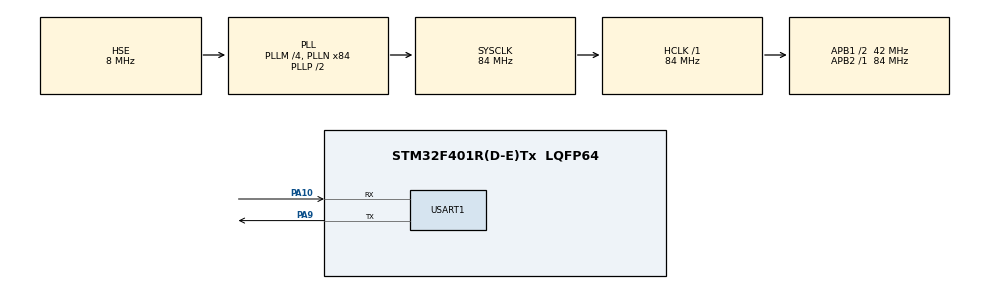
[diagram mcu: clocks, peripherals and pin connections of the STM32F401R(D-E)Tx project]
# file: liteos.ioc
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Mcu.Family=STM32F4
Mcu.Name=STM32F401R(D-E)Tx
Mcu.Package=LQFP64
NVIC.PriorityGroup=NVIC_PRIORITYGROUP_4
PA10.Mode=Asynchronous
PA10.Signal=USART1_RX
PA13.Mode=Serial_Wire
PA13.Signal=SYS_JTMS-SWDIO
PA14.Mode=Serial_Wire
PA14.Signal=SYS_JTCK-SWCLK
PA9.Mode=Asynchronous
PA9.Signal=USART1_TX
PH0\ -\ OSC_IN.Mode=HSE-External-Oscillator
PH0\ -\ OSC_IN.Signal=RCC_OSC_IN
PH1\ -\ OSC_OUT.Mode=HSE-External-Oscillator
PH1\ -\ OSC_OUT.Signal=RCC_OSC_OUT
ProjectManager.HeapSize=0x200
ProjectManager.StackSize=0x400
ProjectManager.TargetToolchain=STM32CubeIDE
RCC.48MHZClocksFreq_Value=42000000
RCC.AHBFreq_Value=84000000
RCC.APB1CLKDivider=RCC_HCLK_DIV2
RCC.APB1Freq_Value=42000000
RCC.APB1TimFreq_Value=84000000
RCC.APB2Freq_Value=84000000
RCC.APB2TimFreq_Value=84000000
RCC.CortexFreq_Value=84000000
RCC.HCLKFreq_Value=84000000
RCC.HSE_VALUE=8000000
RCC.HSI_VALUE=16000000
RCC.LSE_VALUE=32768
RCC.PLLM=4
RCC.PLLN=84
RCC.PLLSourceVirtual=RCC_PLLSOURCE_HSE
RCC.SYSCLKFreq_VALUE=84000000
RCC.SYSCLKSource=RCC_SYSCLKSOURCE_PLLCLK
RCC.VCOOutputFreq_Value=168000000
USART1.VirtualMode=VM_ASYNC
board=custom

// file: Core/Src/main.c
/* USER CODE BEGIN Header */
/**
  ******************************************************************************
  * @file           : main.c
  * @brief          : Main program body
  ******************************************************************************
  * @attention
  *
  * Copyright (c) 2023 STMicroelectronics.
  * All rights reserved.
  *
  * This software is licensed under terms that can be found in the LICENSE file
  * in the root directory of this software component.
  * If no LICENSE file comes with this software, it is provided AS-IS.
  *
  ******************************************************************************
  */
/* USER CODE END Header */
#include "main.h"
#include "usart.h"
#include "gpio.h"

/* USER CODE BEGIN Includes */
#include "stdio.h"
//#include "los_sys.h"
//#include "los_task.h"
#include "los_memory.h"
#include "string.h"
#include "los_task.h"

/* USER CODE END Includes */

/* USER CODE BEGIN PV */
UINT32 TASK1_Handle;
UINT32 TASK2_Handle;
/* USER CODE END PV */

void SystemClock_Config(void);

/* USER CODE BEGIN 0 */
#ifdef __GNUC__
#define PUTCHAR_PROTOTYPE int __io_putchar(int ch)
#else
#define PUTCHAR_PROTOTYPE int fputc(int ch, FILE *f)
#endif

PUTCHAR_PROTOTYPE
{
    HAL_UART_Transmit(&huart1, (uint8_t *)&ch, 1 , 0xffff);
    return ch;
}

static void Task1(VOID)
{
    unsigned int sp = 1;
    printf("task1 start\n");
    while(1) {

        printf("clock: %ud\n",sp);
        LOS_TaskDelay(100);
    }
}
static void Task2(VOID)
{
    unsigned int sp = 1;
    printf("task2 start\n");
    while(1) {
        printf("clock: %ud\n",sp);
        LOS_TaskDelay(50);
    }
}
UINT32  AppTaskCreate(UINT32 *Handle,UINT32 prio,char* task_name,TSK_ENTRY_FUNC task_func,UINT32 stack_size){
    TSK_INIT_PARAM_S task_init_param;
    task_init_param.usTaskPrio = prio;
    strcpy(task_init_param.pcName,task_name);
    task_init_param.pfnTaskEntry=task_func;
    task_init_param.uwStackSize = stack_size;
    UINT32 uwRet = LOS_OK;
    uwRet = LOS_TaskCreate(Handle,&task_init_param);
    if(uwRet != LOS_OK)
    {
        printf("Led1Task create failed,%X\n",uwRet);
        return uwRet;
    }
    return LOS_OK;
}
/* USER CODE END 0 */

int main(void)
{

  /* MCU Configuration--------------------------------------------------------*/

  /* Reset of all peripherals, Initializes the Flash interface and the Systick. */
  HAL_Init();

  /* Configure the system clock */
  SystemClock_Config();

  /* Initialize all configured peripherals */
  MX_GPIO_Init();
  MX_USART1_UART_Init();
  /* USER CODE BEGIN 2 */
    printf("test\n");
    LOS_KernelInit();
    int uwRet = AppTaskCreate(&TASK1_Handle,4,"usart1",(TSK_ENTRY_FUNC) Task1,512);
    if(uwRet != LOS_OK) {
        printf("LOS Creat task failed\r\n");
        //return LOS_NOK;
    }
    uwRet = AppTaskCreate(&TASK2_Handle,4,"usart2",(TSK_ENTRY_FUNC) Task2,512);
    if(uwRet != LOS_OK) {
        printf("LOS Creat task failed\r\n");
        //return LOS_NOK;
    }
    LOS_Start();
  /* USER CODE END 2 */

  /* Infinite loop */
  /* USER CODE BEGIN WHILE */
  while (1)
  {
      printf("1111\n");
    /* USER CODE END WHILE */

  }
}

void SystemClock_Config(void)
{
  RCC_OscInitTypeDef RCC_OscInitStruct = {0};
  RCC_ClkInitTypeDef RCC_ClkInitStruct = {0};

  /** Configure the main internal regulator output voltage
  */
  __HAL_RCC_PWR_CLK_ENABLE();
  __HAL_PWR_VOLTAGESCALING_CONFIG(PWR_REGULATOR_VOLTAGE_SCALE2);

  /** Initializes the RCC Oscillators according to the specified parameters
  * in the RCC_OscInitTypeDef structure.
  */
  RCC_OscInitStruct.OscillatorType = RCC_OSCILLATORTYPE_HSE;
  RCC_OscInitStruct.HSEState = RCC_HSE_ON;
  RCC_OscInitStruct.PLL.PLLState = RCC_PLL_ON;
  RCC_OscInitStruct.PLL.PLLSource = RCC_PLLSOURCE_HSE;
  RCC_OscInitStruct.PLL.PLLM = 4;
  RCC_OscInitStruct.PLL.PLLN = 84;
  RCC_OscInitStruct.PLL.PLLP = RCC_PLLP_DIV2;
  RCC_OscInitStruct.PLL.PLLQ = 4;
  if (HAL_RCC_OscConfig(&RCC_OscInitStruct) != HAL_OK)
  {
    Error_Handler();
  }

  /** Initializes the CPU, AHB and APB buses clocks
  */
  RCC_ClkInitStruct.ClockType = RCC_CLOCKTYPE_HCLK|RCC_CLOCKTYPE_SYSCLK
                              |RCC_CLOCKTYPE_PCLK1|RCC_CLOCKTYPE_PCLK2;
  RCC_ClkInitStruct.SYSCLKSource = RCC_SYSCLKSOURCE_PLLCLK;
  RCC_ClkInitStruct.AHBCLKDivider = RCC_SYSCLK_DIV1;
  RCC_ClkInitStruct.APB1CLKDivider = RCC_HCLK_DIV2;
  RCC_ClkInitStruct.APB2CLKDivider = RCC_HCLK_DIV1;

  if (HAL_RCC_ClockConfig(&RCC_ClkInitStruct, FLASH_LATENCY_2) != HAL_OK)
  {
    Error_Handler();
  }
}

void Error_Handler(void)
{
  __disable_irq();
  while (1)
  {
  }
}
